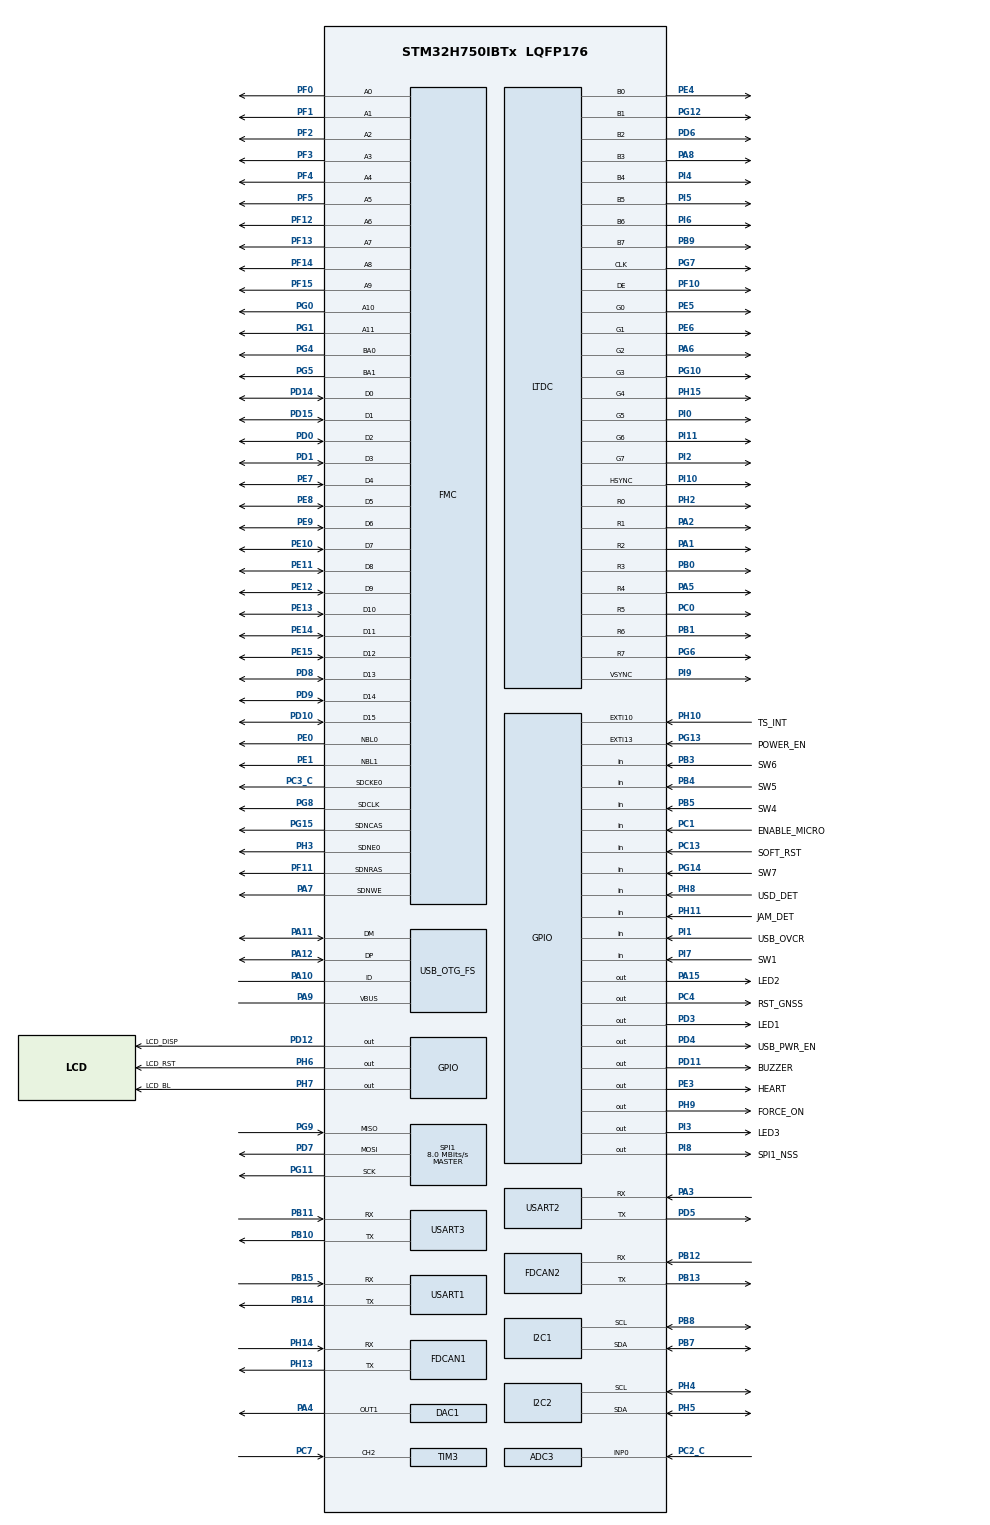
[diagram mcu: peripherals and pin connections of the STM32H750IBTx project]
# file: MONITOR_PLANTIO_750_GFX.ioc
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ADC3.Channel-0\#ChannelRegularConversion=ADC_CHANNEL_0
ADC3.ContinuousConvMode=ENABLE
ADC3.ConversionDataManagement=ADC_CONVERSIONDATA_DMA_CIRCULAR
ADC3.NbrOfConversionFlag=1
ADC3.OffsetNumber-0\#ChannelRegularConversion=ADC_OFFSET_NONE
ADC3.OffsetSignedSaturation-0\#ChannelRegularConversion=DISABLE
ADC3.Rank-0\#ChannelRegularConversion=1
ADC3.Resolution=ADC_RESOLUTION_12B
ADC3.SamplingTime-0\#ChannelRegularConversion=ADC_SAMPLETIME_1CYCLE_5
Bdma.ADC3.0.Direction=DMA_PERIPH_TO_MEMORY
Bdma.ADC3.0.EventEnable=DISABLE
Bdma.ADC3.0.Instance=BDMA_Channel0
Bdma.ADC3.0.MemDataAlignment=DMA_MDATAALIGN_HALFWORD
Bdma.ADC3.0.MemInc=DMA_MINC_ENABLE
Bdma.ADC3.0.Mode=DMA_CIRCULAR
Bdma.ADC3.0.PeriphDataAlignment=DMA_PDATAALIGN_HALFWORD
Bdma.ADC3.0.PeriphInc=DMA_PINC_DISABLE
Bdma.ADC3.0.Polarity=HAL_DMAMUX_REQ_GEN_RISING
Bdma.ADC3.0.Priority=DMA_PRIORITY_LOW
Bdma.ADC3.0.RequestNumber=1
Bdma.ADC3.0.SignalID=NONE
Bdma.ADC3.0.SyncEnable=DISABLE
Bdma.ADC3.0.SyncPolarity=HAL_DMAMUX_SYNC_NO_EVENT
Bdma.ADC3.0.SyncRequestNumber=1
Bdma.ADC3.0.SyncSignalID=NONE
Bdma.Request0=ADC3
Bdma.RequestsNb=1
CORTEX_M7.AccessPermission_S-Cortex_Memory_Protection_Unit_Region1_Settings_S=MPU_REGION_FULL_ACCESS
CORTEX_M7.AccessPermission_Spec=MPU_REGION_FULL_ACCESS
CORTEX_M7.BaseAddress_S-Cortex_Memory_Protection_Unit_Region1_Settings_S=0x90000000
CORTEX_M7.BaseAddress_Spec=0x90000000
CORTEX_M7.CPU_DCache=Enabled
CORTEX_M7.CPU_ICache=Enabled
CORTEX_M7.Enable_S-Cortex_Memory_Protection_Unit_Region1_Settings_S=MPU_REGION_ENABLE
CORTEX_M7.IsBufferable_S-Cortex_Memory_Protection_Unit_Region1_Settings_S=MPU_ACCESS_BUFFERABLE
CORTEX_M7.IsBufferable_Spec=MPU_ACCESS_BUFFERABLE
CORTEX_M7.IsCacheable_S-Cortex_Memory_Protection_Unit_Region1_Settings_S=MPU_ACCESS_CACHEABLE
CORTEX_M7.IsCacheable_Spec=MPU_ACCESS_CACHEABLE
CORTEX_M7.IsShareable_Spec=MPU_ACCESS_NOT_SHAREABLE
CORTEX_M7.Size_S-Cortex_Memory_Protection_Unit_Region1_Settings_S=MPU_REGION_SIZE_16MB
CORTEX_M7.Size_Spec=MPU_REGION_SIZE_64MB
CORTEX_M7.SubRegionDisable_Spec=0
CORTEX_M7.default_mode_Activation=1
DAC1.DAC_Channel-DAC_OUT1=DAC_CHANNEL_1
DMA2D.AlphaInvertedForeground=DMA2D_REGULAR_ALPHA
DMA2D.AlphaModeForeground=DMA2D_NO_MODIF_ALPHA
DMA2D.ColorMode=DMA2D_OUTPUT_RGB565
DMA2D.InputAlphaForeground=255
FDCAN1.AutoRetransmission=ENABLE
FDCAN1.CalculateBaudRateNominal=250000
FDCAN1.CalculateTimeBitNominal=4000
FDCAN1.CalculateTimeQuantumNominal=40.0
FDCAN1.DataPrescaler=4
FDCAN1.DataSyncJumpWidth=12
FDCAN1.DataTimeSeg1=12
FDCAN1.DataTimeSeg2=12
FDCAN1.ExtFiltersNbr=1
FDCAN1.NominalPrescaler=1
FDCAN1.NominalSyncJumpWidth=2
FDCAN1.NominalTimeSeg1=97
FDCAN1.NominalTimeSeg2=2
FDCAN1.RxFifo0ElmtsNbr=1
FDCAN1.TxBuffersNbr=16
FDCAN1.TxEventsNbr=1
FDCAN1.TxFifoQueueElmtsNbr=16
FDCAN2.AutoRetransmission=ENABLE
FDCAN2.CalculateBaudRateNominal=250000
FDCAN2.CalculateTimeBitNominal=4000
FDCAN2.CalculateTimeQuantumNominal=40.0
FDCAN2.DataPrescaler=4
FDCAN2.DataSyncJumpWidth=12
FDCAN2.DataTimeSeg1=12
FDCAN2.DataTimeSeg2=12
FDCAN2.ExtFiltersNbr=1
FDCAN2.MessageRAMOffset=10
FDCAN2.NominalPrescaler=1
FDCAN2.NominalSyncJumpWidth=2
FDCAN2.NominalTimeSeg1=97
FDCAN2.NominalTimeSeg2=2
FDCAN2.RxFifo1ElmtsNbr=1
FDCAN2.TxBuffersNbr=16
FDCAN2.TxEventsNbr=1
FDCAN2.TxFifoQueueElmtsNbr=16
FMC.CASLatency1=FMC_SDRAM_CAS_LATENCY_3
FMC.ExitSelfRefreshDelay1=11
FMC.LoadToActiveDelay1=2
FMC.RCDDelay1=3
FMC.RPDelay1=3
FMC.RPDelay2=3
FMC.ReadBurst1=FMC_SDRAM_RBURST_ENABLE
FMC.ReadBurst2=FMC_SDRAM_RBURST_ENABLE
FMC.ReadPipeDelay1=FMC_SDRAM_RPIPE_DELAY_2
FMC.RowCycleDelay1=10
FMC.RowCycleDelay2=10
FMC.SDClockPeriod1=FMC_SDRAM_CLOCK_PERIOD_3
FMC.SDClockPeriod2=FMC_SDRAM_CLOCK_PERIOD_3
FMC.SelfRefreshTime1=7
FMC.WriteRecoveryTime1=4
FREERTOS.Queues01=adcQueue,4,uint16_t,0,Dynamic,NULL,NULL;butQueue,8,uint8_t,0,Dynamic,NULL,NULL;ts_Touch,12,uint16_t,0,Dynamic,NULL,NULL;canQueue,64,uint8_t,0,Dynamic,NULL,NULL
FREERTOS.Tasks01=defaultTask,24,128,StartDefaultTask,Default,NULL,Dynamic,NULL,NULL;myTouchGFX,24,10000,StartTGFXTask,Default,NULL,Dynamic,NULL,NULL;adcTask,16,512,StartADCTask,Default,NULL,Dynamic,NULL,NULL;tsTask,25,1000,StartTS,Default,NULL,Dynamic,NULL,NULL;CanTask,24,512,StartTask05,Default,NULL,Dynamic,NULL,NULL
FREERTOS.configTOTAL_HEAP_SIZE=50000
FREERTOS.configUSE_NEWLIB_REENTRANT=1
I2C1.Timing=0x307075B1
I2C2.Timing=0x307075B1
LTDC.ActiveW=800
LTDC.Alpha0_L0=255
LTDC.Alpha_L0=255
LTDC.BlendingFactor1_L0=LTDC_BLENDING_FACTOR1_PAxCA
LTDC.BlendingFactor2_L0=LTDC_BLENDING_FACTOR2_PAxCA
LTDC.Blue_L0=0
LTDC.DEPolarity=LTDC_DEPOLARITY_AL
LTDC.FBStartAdress_L0=0xC0000000
LTDC.Green_L0=0
LTDC.HBP=24
LTDC.HFP=16
LTDC.HSPolarity=LTDC_HSPOLARITY_AL
LTDC.HSync=9
LTDC.ImageHeight_L0=480
LTDC.ImageWidth_L0=800
LTDC.Layers=0
LTDC.PCPolarity=LTDC_PCPOLARITY_IPC
LTDC.PixelFormat_L0=LTDC_PIXEL_FORMAT_RGB565
LTDC.Red_L0=0
LTDC.VBP=16
LTDC.VFP=8
LTDC.VSPolarity=LTDC_VSPOLARITY_AL
LTDC.VSync=9
LTDC.WindowX1_L0=800
LTDC.WindowY1_L0=480
Mcu.Family=STM32H7
Mcu.Name=STM32H750IBTx
Mcu.Package=LQFP176
NVIC.BDMA_Channel0_IRQn=true\:5\:0\:false\:false\:true\:true\:false\:true\:true
NVIC.DMA2D_IRQn=true\:5\:0\:false\:false\:true\:true\:true\:true\:true
NVIC.FDCAN1_IT0_IRQn=true\:5\:0\:true\:false\:true\:true\:true\:true\:true
NVIC.FDCAN2_IT1_IRQn=true\:5\:0\:true\:false\:true\:true\:true\:true\:true
NVIC.LTDC_IRQn=true\:5\:0\:true\:false\:true\:true\:true\:true\:true
NVIC.PriorityGroup=NVIC_PRIORITYGROUP_4
NVIC.TIM6_DAC_IRQn=true\:15\:0\:false\:false\:true\:false\:false\:true\:true
NVIC.TIM7_IRQn=true\:8\:0\:true\:false\:true\:true\:true\:true\:true
NVIC.TimeBase=TIM6_DAC_IRQn
NVIC.TimeBaseIP=TIM6
PA1.GPIO_Speed=GPIO_SPEED_FREQ_VERY_HIGH
PA1.Mode=RGB888
PA1.PinAttribute=Free
PA1.Signal=LTDC_R2
PA10.Mode=OTG/Dual_Role_Device
PA10.PinAttribute=Free
PA10.Signal=USB_OTG_FS_ID
PA11.Mode=OTG/Dual_Role_Device
PA11.PinAttribute=Free
PA11.Signal=USB_OTG_FS_DM
PA12.Mode=OTG/Dual_Role_Device
PA12.PinAttribute=Free
PA12.Signal=USB_OTG_FS_DP
PA13\ (JTMS/SWDIO).Mode=Serial_Wire
PA13\ (JTMS/SWDIO).PinAttribute=Free
PA13\ (JTMS/SWDIO).Signal=DEBUG_JTMS-SWDIO
PA14\ (JTCK/SWCLK).Mode=Serial_Wire
PA14\ (JTCK/SWCLK).PinAttribute=Free
PA14\ (JTCK/SWCLK).Signal=DEBUG_JTCK-SWCLK
PA15\ (JTDI).GPIO_Label=LED2
PA15\ (JTDI).PinAttribute=Free
PA15\ (JTDI).Signal=GPIO_Output
PA2.GPIO_Speed=GPIO_SPEED_FREQ_VERY_HIGH
PA2.Mode=RGB888
PA2.PinAttribute=Free
PA2.Signal=LTDC_R1
PA3.Mode=Asynchronous
PA3.PinAttribute=Free
PA3.Signal=USART2_RX
PA4.PinAttribute=Free
PA4.Signal=COMP_DAC11_group
PA5.GPIO_Speed=GPIO_SPEED_FREQ_VERY_HIGH
PA5.Mode=RGB888
PA5.PinAttribute=Free
PA5.Signal=LTDC_R4
PA6.GPIO_Speed=GPIO_SPEED_FREQ_VERY_HIGH
PA6.Mode=RGB888
PA6.PinAttribute=Free
PA6.Signal=LTDC_G2
PA7.GPIO_PuPd=GPIO_NOPULL
PA7.GPIO_Speed_High_Default=GPIO_SPEED_FREQ_VERY_HIGH
PA7.PinAttribute=Free
PA7.Signal=FMC_SDNWE
PA8.GPIO_Speed=GPIO_SPEED_FREQ_VERY_HIGH
PA8.Mode=RGB888
PA8.PinAttribute=Free
PA8.Signal=LTDC_B3
PA9.Mode=Activate_VBUS
PA9.PinAttribute=Free
PA9.Signal=USB_OTG_FS_VBUS
PB0.GPIO_Speed=GPIO_SPEED_FREQ_VERY_HIGH
PB0.Mode=RGB888
PB0.PinAttribute=Free
PB0.Signal=LTDC_R3
PB1.GPIO_Speed=GPIO_SPEED_FREQ_VERY_HIGH
PB1.Mode=RGB888
PB1.PinAttribute=Free
PB1.Signal=LTDC_R6
PB10.Mode=Asynchronous
PB10.PinAttribute=Free
PB10.Signal=USART3_TX
PB11.Mode=Asynchronous
PB11.PinAttribute=Free
PB11.Signal=USART3_RX
PB12.Mode=FDCAN_Activate
PB12.PinAttribute=Free
PB12.Signal=FDCAN2_RX
PB13.Mode=FDCAN_Activate
PB13.PinAttribute=Free
PB13.Signal=FDCAN2_TX
PB14.Mode=Asynchronous
PB14.PinAttribute=Free
PB14.Signal=USART1_TX
PB15.Mode=Asynchronous
PB15.PinAttribute=Free
PB15.Signal=USART1_RX
PB3\ (JTDO/TRACESWO).GPIO_Label=SW6
PB3\ (JTDO/TRACESWO).PinAttribute=Free
PB3\ (JTDO/TRACESWO).Signal=GPIO_Input
PB4\ (NJTRST).GPIO_Label=SW5
PB4\ (NJTRST).PinAttribute=Free
PB4\ (NJTRST).Signal=GPIO_Input
PB5.GPIO_Label=SW4
PB5.PinAttribute=Free
PB5.Signal=GPIO_Input
PB7.GPIO_Speed=GPIO_SPEED_FREQ_HIGH
PB7.Mode=I2C
PB7.PinAttribute=Free
PB7.Signal=I2C1_SDA
PB8.GPIO_Speed=GPIO_SPEED_FREQ_HIGH
PB8.Mode=I2C
PB8.PinAttribute=Free
PB8.Signal=I2C1_SCL
PB9.GPIO_Speed=GPIO_SPEED_FREQ_VERY_HIGH
PB9.Mode=RGB888
PB9.PinAttribute=Free
PB9.Signal=LTDC_B7
PC0.GPIO_Speed=GPIO_SPEED_FREQ_VERY_HIGH
PC0.Mode=RGB888
PC0.PinAttribute=Free
PC0.Signal=LTDC_R5
PC1.GPIO_Label=ENABLE_MICRO
PC1.PinAttribute=Free
PC1.Signal=GPIO_Input
PC13.GPIO_Label=SOFT_RST
PC13.PinAttribute=Free
PC13.Signal=GPIO_Input
PC2_C.Mode=IN0-Single-Ended
PC2_C.PinAttribute=Free
PC2_C.Signal=ADC3_INP0
PC3_C.GPIO_PuPd=GPIO_NOPULL
PC3_C.GPIO_Speed_High_Default=GPIO_SPEED_FREQ_VERY_HIGH
PC3_C.Mode=SdramChipSelect1_1
PC3_C.PinAttribute=Free
PC3_C.Signal=FMC_SDCKE0
PC4.GPIO_Label=RST_GNSS
PC4.PinAttribute=Free
PC4.Signal=GPIO_Output
PC7.PinAttribute=Free
PC7.Signal=S_TIM3_CH2
PD0.GPIO_PuPd=GPIO_NOPULL
PD0.GPIO_Speed_High_Default=GPIO_SPEED_FREQ_VERY_HIGH
PD0.PinAttribute=Free
PD0.Signal=FMC_D2_DA2
PD1.GPIO_PuPd=GPIO_NOPULL
PD1.GPIO_Speed_High_Default=GPIO_SPEED_FREQ_VERY_HIGH
PD1.PinAttribute=Free
PD1.Signal=FMC_D3_DA3
PD10.GPIO_PuPd=GPIO_NOPULL
PD10.GPIO_Speed_High_Default=GPIO_SPEED_FREQ_VERY_HIGH
PD10.PinAttribute=Free
PD10.Signal=FMC_D15_DA15
PD11.GPIO_Label=BUZZER
PD11.PinAttribute=Free
PD11.Signal=GPIO_Output
PD12.GPIO_Label=LCD_DISP
PD12.PinAttribute=Free
PD12.Signal=GPIO_Output
PD14.GPIO_PuPd=GPIO_NOPULL
PD14.GPIO_Speed_High_Default=GPIO_SPEED_FREQ_VERY_HIGH
PD14.PinAttribute=Free
PD14.Signal=FMC_D0_DA0
PD15.GPIO_PuPd=GPIO_NOPULL
PD15.GPIO_Speed_High_Default=GPIO_SPEED_FREQ_VERY_HIGH
PD15.PinAttribute=Free
PD15.Signal=FMC_D1_DA1
PD3.GPIO_Label=LED1
PD3.PinAttribute=Free
PD3.Signal=GPIO_Output
PD4.GPIO_Label=USB_PWR_EN
PD4.PinAttribute=Free
PD4.Signal=GPIO_Output
PD5.Mode=Asynchronous
PD5.PinAttribute=Free
PD5.Signal=USART2_TX
PD6.GPIO_Speed=GPIO_SPEED_FREQ_VERY_HIGH
PD6.Mode=RGB888
PD6.PinAttribute=Free
PD6.Signal=LTDC_B2
PD7.Mode=Full_Duplex_Master
PD7.PinAttribute=Free
PD7.Signal=SPI1_MOSI
PD8.GPIO_PuPd=GPIO_NOPULL
PD8.GPIO_Speed_High_Default=GPIO_SPEED_FREQ_VERY_HIGH
PD8.PinAttribute=Free
PD8.Signal=FMC_D13_DA13
PD9.GPIO_PuPd=GPIO_NOPULL
PD9.GPIO_Speed_High_Default=GPIO_SPEED_FREQ_VERY_HIGH
PD9.PinAttribute=Free
PD9.Signal=FMC_D14_DA14
PE0.PinAttribute=Free
PE0.Signal=FMC_NBL0
PE1.PinAttribute=Free
PE1.Signal=FMC_NBL1
PE10.GPIO_PuPd=GPIO_NOPULL
PE10.GPIO_Speed_High_Default=GPIO_SPEED_FREQ_VERY_HIGH
PE10.PinAttribute=Free
PE10.Signal=FMC_D7_DA7
PE11.GPIO_PuPd=GPIO_NOPULL
PE11.GPIO_Speed_High_Default=GPIO_SPEED_FREQ_VERY_HIGH
PE11.PinAttribute=Free
PE11.Signal=FMC_D8_DA8
PE12.GPIO_PuPd=GPIO_NOPULL
PE12.GPIO_Speed_High_Default=GPIO_SPEED_FREQ_VERY_HIGH
PE12.PinAttribute=Free
PE12.Signal=FMC_D9_DA9
PE13.GPIO_PuPd=GPIO_NOPULL
PE13.GPIO_Speed_High_Default=GPIO_SPEED_FREQ_VERY_HIGH
PE13.PinAttribute=Free
PE13.Signal=FMC_D10_DA10
PE14.GPIO_PuPd=GPIO_NOPULL
PE14.GPIO_Speed_High_Default=GPIO_SPEED_FREQ_VERY_HIGH
PE14.PinAttribute=Free
PE14.Signal=FMC_D11_DA11
PE15.GPIO_PuPd=GPIO_NOPULL
PE15.GPIO_Speed_High_Default=GPIO_SPEED_FREQ_VERY_HIGH
PE15.PinAttribute=Free
PE15.Signal=FMC_D12_DA12
PE3.GPIO_Label=HEART
PE3.PinAttribute=Free
PE3.Signal=GPIO_Output
PE4.GPIO_Speed=GPIO_SPEED_FREQ_VERY_HIGH
PE4.Mode=RGB888
PE4.PinAttribute=Free
PE4.Signal=LTDC_B0
PE5.GPIO_Speed=GPIO_SPEED_FREQ_VERY_HIGH
PE5.Mode=RGB888
PE5.PinAttribute=Free
PE5.Signal=LTDC_G0
PE6.GPIO_Speed=GPIO_SPEED_FREQ_VERY_HIGH
PE6.Mode=RGB888
PE6.PinAttribute=Free
PE6.Signal=LTDC_G1
PE7.GPIO_PuPd=GPIO_NOPULL
PE7.GPIO_Speed_High_Default=GPIO_SPEED_FREQ_VERY_HIGH
PE7.PinAttribute=Free
PE7.Signal=FMC_D4_DA4
PE8.GPIO_PuPd=GPIO_NOPULL
PE8.GPIO_Speed_High_Default=GPIO_SPEED_FREQ_VERY_HIGH
PE8.PinAttribute=Free
PE8.Signal=FMC_D5_DA5
PE9.GPIO_PuPd=GPIO_NOPULL
PE9.GPIO_Speed_High_Default=GPIO_SPEED_FREQ_VERY_HIGH
PE9.PinAttribute=Free
PE9.Signal=FMC_D6_DA6
PF0.GPIO_PuPd=GPIO_NOPULL
PF0.GPIO_Speed_High_Default=GPIO_SPEED_FREQ_VERY_HIGH
PF0.PinAttribute=Free
PF0.Signal=FMC_A0
PF1.GPIO_PuPd=GPIO_NOPULL
PF1.GPIO_Speed_High_Default=GPIO_SPEED_FREQ_VERY_HIGH
PF1.PinAttribute=Free
PF1.Signal=FMC_A1
PF10.GPIO_Speed=GPIO_SPEED_FREQ_VERY_HIGH
PF10.Mode=RGB888
PF10.PinAttribute=Free
PF10.Signal=LTDC_DE
PF11.GPIO_PuPd=GPIO_NOPULL
PF11.GPIO_Speed_High_Default=GPIO_SPEED_FREQ_VERY_HIGH
PF11.PinAttribute=Free
PF11.Signal=FMC_SDNRAS
PF12.GPIO_PuPd=GPIO_NOPULL
PF12.GPIO_Speed_High_Default=GPIO_SPEED_FREQ_VERY_HIGH
PF12.PinAttribute=Free
PF12.Signal=FMC_A6
PF13.GPIO_PuPd=GPIO_NOPULL
PF13.GPIO_Speed_High_Default=GPIO_SPEED_FREQ_VERY_HIGH
PF13.PinAttribute=Free
PF13.Signal=FMC_A7
PF14.GPIO_PuPd=GPIO_NOPULL
PF14.GPIO_Speed_High_Default=GPIO_SPEED_FREQ_VERY_HIGH
PF14.PinAttribute=Free
PF14.Signal=FMC_A8
PF15.GPIO_PuPd=GPIO_NOPULL
PF15.GPIO_Speed_High_Default=GPIO_SPEED_FREQ_VERY_HIGH
PF15.PinAttribute=Free
PF15.Signal=FMC_A9
PF2.GPIO_PuPd=GPIO_NOPULL
PF2.GPIO_Speed_High_Default=GPIO_SPEED_FREQ_VERY_HIGH
PF2.PinAttribute=Free
PF2.Signal=FMC_A2
PF3.GPIO_PuPd=GPIO_NOPULL
PF3.GPIO_Speed_High_Default=GPIO_SPEED_FREQ_VERY_HIGH
PF3.PinAttribute=Free
PF3.Signal=FMC_A3
PF4.GPIO_PuPd=GPIO_NOPULL
PF4.GPIO_Speed_High_Default=GPIO_SPEED_FREQ_VERY_HIGH
PF4.PinAttribute=Free
PF4.Signal=FMC_A4
PF5.GPIO_PuPd=GPIO_NOPULL
PF5.GPIO_Speed_High_Default=GPIO_SPEED_FREQ_VERY_HIGH
PF5.PinAttribute=Free
PF5.Signal=FMC_A5
PG0.GPIO_PuPd=GPIO_NOPULL
PG0.GPIO_Speed_High_Default=GPIO_SPEED_FREQ_VERY_HIGH
PG0.PinAttribute=Free
PG0.Signal=FMC_A10
PG1.GPIO_PuPd=GPIO_NOPULL
PG1.GPIO_Speed_High_Default=GPIO_SPEED_FREQ_VERY_HIGH
PG1.PinAttribute=Free
PG1.Signal=FMC_A11
PG10.GPIO_Speed=GPIO_SPEED_FREQ_VERY_HIGH
PG10.Mode=RGB888
PG10.PinAttribute=Free
PG10.Signal=LTDC_G3
PG11.Mode=Full_Duplex_Master
PG11.Signal=SPI1_SCK
PG12.GPIO_Speed=GPIO_SPEED_FREQ_VERY_HIGH
PG12.Mode=RGB888
PG12.PinAttribute=Free
PG12.Signal=LTDC_B1
PG13.GPIO_Label=POWER_EN
PG13.PinAttribute=Free
PG13.Signal=GPXTI13
PG14.GPIO_Label=SW7
PG14.PinAttribute=Free
PG14.Signal=GPIO_Input
PG15.GPIO_PuPd=GPIO_NOPULL
PG15.GPIO_Speed_High_Default=GPIO_SPEED_FREQ_VERY_HIGH
PG15.PinAttribute=Free
PG15.Signal=FMC_SDNCAS
PG4.GPIO_PuPd=GPIO_NOPULL
PG4.GPIO_Speed_High_Default=GPIO_SPEED_FREQ_VERY_HIGH
PG4.PinAttribute=Free
PG4.Signal=FMC_A14_BA0
PG5.GPIO_PuPd=GPIO_NOPULL
PG5.GPIO_Speed_High_Default=GPIO_SPEED_FREQ_VERY_HIGH
PG5.PinAttribute=Free
PG5.Signal=FMC_A15_BA1
PG6.GPIO_Speed=GPIO_SPEED_FREQ_VERY_HIGH
PG6.Mode=RGB888
PG6.PinAttribute=Free
PG6.Signal=LTDC_R7
PG7.GPIO_Speed=GPIO_SPEED_FREQ_VERY_HIGH
PG7.Mode=RGB888
PG7.PinAttribute=Free
PG7.Signal=LTDC_CLK
PG8.GPIO_PuPd=GPIO_NOPULL
PG8.GPIO_Speed_High_Default=GPIO_SPEED_FREQ_VERY_HIGH
PG8.PinAttribute=Free
PG8.Signal=FMC_SDCLK
PG9.Mode=Full_Duplex_Master
PG9.PinAttribute=Free
PG9.Signal=SPI1_MISO
PH0-OSC_IN\ (PH0).Mode=HSE-External-Oscillator
PH0-OSC_IN\ (PH0).PinAttribute=Free
PH0-OSC_IN\ (PH0).Signal=RCC_OSC_IN
PH1-OSC_OUT\ (PH1).Mode=HSE-External-Oscillator
PH1-OSC_OUT\ (PH1).PinAttribute=Free
PH1-OSC_OUT\ (PH1).Signal=RCC_OSC_OUT
PH10.GPIO_Label=TS_INT
PH10.PinAttribute=Free
PH10.Signal=GPXTI10
PH11.GPIO_Label=JAM_DET
PH11.PinAttribute=Free
PH11.Signal=GPIO_Input
PH13.Mode=FDCAN_Activate
PH13.PinAttribute=Free
PH13.Signal=FDCAN1_TX
PH14.Mode=FDCAN_Activate
PH14.PinAttribute=Free
PH14.Signal=FDCAN1_RX
PH15.GPIO_Speed=GPIO_SPEED_FREQ_VERY_HIGH
PH15.Mode=RGB888
PH15.PinAttribute=Free
PH15.Signal=LTDC_G4
PH2.GPIO_Speed=GPIO_SPEED_FREQ_VERY_HIGH
PH2.Mode=RGB888
PH2.PinAttribute=Free
PH2.Signal=LTDC_R0
PH3.GPIO_PuPd=GPIO_NOPULL
PH3.GPIO_Speed_High_Default=GPIO_SPEED_FREQ_VERY_HIGH
PH3.Mode=SdramChipSelect1_1
PH3.PinAttribute=Free
PH3.Signal=FMC_SDNE0
PH4.Mode=I2C
PH4.PinAttribute=Free
PH4.Signal=I2C2_SCL
PH5.Mode=I2C
PH5.PinAttribute=Free
PH5.Signal=I2C2_SDA
PH6.GPIO_Label=LCD_RST
PH6.PinAttribute=Free
PH6.Signal=GPIO_Output
PH7.GPIO_Label=LCD_BL
PH7.PinAttribute=Free
PH7.Signal=GPIO_Output
PH8.GPIO_Label=USD_DET
PH8.PinAttribute=Free
PH8.Signal=GPIO_Input
PH9.GPIO_Label=FORCE_ON
PH9.PinAttribute=Free
PH9.Signal=GPIO_Output
PI0.GPIO_Speed=GPIO_SPEED_FREQ_VERY_HIGH
PI0.Mode=RGB888
PI0.PinAttribute=Free
PI0.Signal=LTDC_G5
PI1.GPIO_Label=USB_OVCR
PI1.PinAttribute=Free
PI1.Signal=GPIO_Input
PI10.GPIO_Speed=GPIO_SPEED_FREQ_VERY_HIGH
PI10.Mode=RGB888
PI10.PinAttribute=Free
PI10.Signal=LTDC_HSYNC
PI11.GPIO_Speed=GPIO_SPEED_FREQ_VERY_HIGH
PI11.Mode=RGB888
PI11.PinAttribute=Free
PI11.Signal=LTDC_G6
PI2.GPIO_Speed=GPIO_SPEED_FREQ_VERY_HIGH
PI2.Mode=RGB888
PI2.PinAttribute=Free
PI2.Signal=LTDC_G7
PI3.GPIO_Label=LED3
PI3.PinAttribute=Free
PI3.Signal=GPIO_Output
PI4.GPIO_Speed=GPIO_SPEED_FREQ_VERY_HIGH
PI4.Mode=RGB888
PI4.PinAttribute=Free
PI4.Signal=LTDC_B4
PI5.GPIO_Speed=GPIO_SPEED_FREQ_VERY_HIGH
PI5.Mode=RGB888
PI5.PinAttribute=Free
PI5.Signal=LTDC_B5
PI6.GPIO_Speed=GPIO_SPEED_FREQ_VERY_HIGH
PI6.Mode=RGB888
PI6.PinAttribute=Free
PI6.Signal=LTDC_B6
PI7.GPIO_Label=SW1
PI7.PinAttribute=Free
PI7.Signal=GPIO_Input
PI8.GPIO_Label=SPI1_NSS
PI8.PinAttribute=Free
PI8.Signal=GPIO_Output
PI9.GPIO_Speed=GPIO_SPEED_FREQ_VERY_HIGH
PI9.Mode=RGB888
PI9.PinAttribute=Free
PI9.Signal=LTDC_VSYNC
ProjectManager.HeapSize=0x1000
ProjectManager.StackSize=0x2000
ProjectManager.TargetToolchain=STM32CubeIDE
RCC.ADCFreq_Value=75000000
RCC.APB1Freq_Value=120000000
RCC.APB2Freq_Value=120000000
RCC.APB3Freq_Value=120000000
RCC.APB4Freq_Value=120000000
RCC.CortexFreq_Value=480000000
RCC.D1PPRE=RCC_APB3_DIV2
RCC.D2PPRE1=RCC_APB1_DIV2
RCC.D2PPRE2=RCC_APB2_DIV2
RCC.D3PPRE=RCC_APB4_DIV2
RCC.DIVM1=5
RCC.DIVM2=2
RCC.DIVM3=2
RCC.DIVN1=192
RCC.DIVN2=12
RCC.DIVN3=12
RCC.DIVQ1=15
RCC.DIVR2=1
RCC.DIVR3=6
RCC.FDCANCLockSelection=RCC_FDCANCLKSOURCE_HSE
RCC.HCLKFreq_Value=240000000
RCC.HPRE=RCC_HCLK_DIV2
RCC.LSE_VALUE=0.03277
RCC.PLL1_VCI_Range-AdvancedSettings=RCC_PLL1VCIRANGE_2
RCC.PLL1_VCO_SEL-AdvancedSettings=RCC_PLL1VCOMEDIUM
RCC.PLL2FRACN=0
RCC.PLL2_VCI_Range-AdvancedSettings=RCC_PLL2VCIRANGE_0
RCC.PLL3FRACN=0
RCC.PLLFRACN=0
RCC.PWR_Regulator_Voltage_Scale=PWR_REGULATOR_VOLTAGE_SCALE0
RCC.QSPICLockSelection=RCC_QSPICLKSOURCE_PLL2
RCC.SYSCLKFreq_VALUE=480000000
RCC.SYSCLKSource=RCC_SYSCLKSOURCE_PLLCLK
RCC.USBFreq_Value=64000000
SH.COMP_DAC11_group.0=DAC1_OUT1,DAC_OUT1
SH.FMC_A0.0=FMC_A0,12b-sda1
SH.FMC_A1.0=FMC_A1,12b-sda1
SH.FMC_A10.0=FMC_A10,12b-sda1
SH.FMC_A11.0=FMC_A11,12b-sda1
SH.FMC_A14_BA0.0=FMC_BA0,FourSdramBanks1
SH.FMC_A15_BA1.0=FMC_BA1,FourSdramBanks1
SH.FMC_A2.0=FMC_A2,12b-sda1
SH.FMC_A3.0=FMC_A3,12b-sda1
SH.FMC_A4.0=FMC_A4,12b-sda1
SH.FMC_A5.0=FMC_A5,12b-sda1
SH.FMC_A6.0=FMC_A6,12b-sda1
SH.FMC_A7.0=FMC_A7,12b-sda1
SH.FMC_A8.0=FMC_A8,12b-sda1
SH.FMC_A9.0=FMC_A9,12b-sda1
SH.FMC_D0_DA0.0=FMC_D0,sd-16b-d1
SH.FMC_D10_DA10.0=FMC_D10,sd-16b-d1
SH.FMC_D11_DA11.0=FMC_D11,sd-16b-d1
SH.FMC_D12_DA12.0=FMC_D12,sd-16b-d1
SH.FMC_D13_DA13.0=FMC_D13,sd-16b-d1
SH.FMC_D14_DA14.0=FMC_D14,sd-16b-d1
SH.FMC_D15_DA15.0=FMC_D15,sd-16b-d1
SH.FMC_D1_DA1.0=FMC_D1,sd-16b-d1
SH.FMC_D2_DA2.0=FMC_D2,sd-16b-d1
SH.FMC_D3_DA3.0=FMC_D3,sd-16b-d1
SH.FMC_D4_DA4.0=FMC_D4,sd-16b-d1
SH.FMC_D5_DA5.0=FMC_D5,sd-16b-d1
SH.FMC_D6_DA6.0=FMC_D6,sd-16b-d1
SH.FMC_D7_DA7.0=FMC_D7,sd-16b-d1
SH.FMC_D8_DA8.0=FMC_D8,sd-16b-d1
SH.FMC_D9_DA9.0=FMC_D9,sd-16b-d1
SH.FMC_NBL0.0=FMC_NBL0,Sd2ByteEnable1
SH.FMC_NBL1.0=FMC_NBL1,Sd2ByteEnable1
SH.FMC_SDCLK.0=FMC_SDCLK,12b-sda1
SH.FMC_SDNCAS.0=FMC_SDNCAS,12b-sda1
SH.FMC_SDNRAS.0=FMC_SDNRAS,12b-sda1
SH.FMC_SDNWE.0=FMC_SDNWE,12b-sda1
SH.S_TIM3_CH2.0=TIM3_CH2,Input_Capture2_from_TI2
SPI1.BaudRatePrescaler=SPI_BAUDRATEPRESCALER_8
SPI1.CalculateBaudRate=8.0 MBits/s
SPI1.Direction=SPI_DIRECTION_2LINES
SPI1.Mode=SPI_MODE_MASTER
SPI1.VirtualType=VM_MASTER
STMicroelectronics.X-CUBE-TOUCHGFX.4.26.1.ApplicationCcGraphicsJjApplication=TouchGFXOoGenerator
STMicroelectronics.X-CUBE-TOUCHGFX.4.26.1.tgfx_address1=0xC0000000
STMicroelectronics.X-CUBE-TOUCHGFX.4.26.1.tgfx_address2=0xC00BB800
STMicroelectronics.X-CUBE-TOUCHGFX.4.26.1.tgfx_buffering_strategy=Single
STMicroelectronics.X-CUBE-TOUCHGFX.4.26.1.tgfx_custom_height=480
STMicroelectronics.X-CUBE-TOUCHGFX.4.26.1.tgfx_display_interface=disp_ltdc
STMicroelectronics.X-CUBE-TOUCHGFX.4.26.1.tgfx_framebuffer_stride=Enabled
STMicroelectronics.X-CUBE-TOUCHGFX.4.26.1.tgfx_hardware_accelerator=dma_2d
STMicroelectronics.X-CUBE-TOUCHGFX.4.26.1.tgfx_location=By Address
STMicroelectronics.X-CUBE-TOUCHGFX.4.26.1.tgfx_oswrapper=CMSIS V2
STMicroelectronics.X-CUBE-TOUCHGFX.4.26.1.tgfx_pixel_format=RGB565\:16
STMicroelectronics.X-CUBE-TOUCHGFX.4.26.1.tgfx_vsync=vsync_ltdc
STMicroelectronics.X-CUBE-TOUCHGFX.4.26.1_IsPackSelfContextualization=true
TIM3.Channel-Input_Capture2_from_TI2=TIM_CHANNEL_2
TIM3.Prescaler=48-1
TIM7.Period=100-1
TIM7.Prescaler=480-1
USART1.VirtualMode-Asynchronous=VM_ASYNC
USART2.VirtualMode-Asynchronous=VM_ASYNC
USART3.VirtualMode-Asynchronous=VM_ASYNC
USB_OTG_FS.VirtualMode=Dual_Role_Device_FS
VP_CRC_VS_CRC.Mode=CRC_Activate
VP_DMA2D_VS_DMA2D.Mode=DMA2D_Activate
VP_FREERTOS_VS_CMSIS_V2.Mode=CMSIS_V2
VP_MEMORYMAP_VS_MEMORYMAP.Mode=CurAppReg
VP_STMicroelectronics.X-CUBE-TOUCHGFX_VS_GraphicsJjApplication_4.26.1.Mode=GraphicsJjApplication
VP_SYS_VS_tim6.Mode=TIM6
VP_TIM7_VS_ClockSourceINT.Mode=Enable_Timer
VP_USB_OTG_FS1_USB_OTG_FS_DRD.Mode=activate_FS
board=custom

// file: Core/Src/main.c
/* USER CODE BEGIN Header */
/**
  ******************************************************************************
  * @file           : main.c
  * @brief          : Main program body
  ******************************************************************************
  * @attention
  *
  * Copyright (c) 2026 STMicroelectronics.
  * All rights reserved.
  *
  * This software is licensed under terms that can be found in the LICENSE file
  * in the root directory of this software component.
  * If no LICENSE file comes with this software, it is provided AS-IS.
  *
  ******************************************************************************
  */
/* USER CODE END Header */
#include "main.h"
#include "FreeRTOS.h"
#include "cmsis_os2.h"
#include "adc.h"
#include "bdma.h"
#include "crc.h"
#include "dac.h"
#include "dma2d.h"
#include "fdcan.h"
#include "i2c.h"
#include "ltdc.h"
#include "spi.h"
#include "tim.h"
#include "usart.h"
#include "usb_otg.h"
#include "gpio.h"
#include "fmc.h"
#include "app_touchgfx.h"

/* USER CODE BEGIN Includes */
#include "touch.h"
/* USER CODE END Includes */

/* USER CODE BEGIN PD */
#define TFT_HOR_RES 800
#define TFT_VER_RES 480
#define TFT_BUFFER_SIZE (TFT_HOR_RES*TFT_VER_RES*2) //1152000 bytes

#define COLOR_BUF (((0x7f>>3)<<11)|((0x7f>>2)<<5)|(0x7f>>3)) // Convert colors to RGB565

/* USER CODE END PD */

/* USER CODE BEGIN PV */
uint16_t* framebuffer = (uint16_t*)0xC0000000;  //16 bpp framebuffer
/* USER CODE END PV */

void SystemClock_Config(void);
static void MPU_Config(void);
void MX_FREERTOS_Init(void);

/* USER CODE BEGIN 0 */
void delay_nop()
{
	__NOP();__NOP();__NOP();__NOP();__NOP();__NOP();__NOP();__NOP();__NOP();__NOP();__NOP();__NOP();
	__NOP();__NOP();__NOP();__NOP();__NOP();__NOP();
}

void delay_us(uint32_t delay)
 {
	uint32_t counter_delay=0;
	while(++counter_delay<delay)
	 {
		delay_nop();
	 }
 }
/* USER CODE END 0 */

int main(void)
{

  /* MPU Configuration--------------------------------------------------------*/
  MPU_Config();

  /* Enable the CPU Cache */

  /* Enable I-Cache---------------------------------------------------------*/
  SCB_EnableICache();

  /* Enable D-Cache---------------------------------------------------------*/
  SCB_EnableDCache();

  /* MCU Configuration--------------------------------------------------------*/

  /* Reset of all peripherals, Initializes the Flash interface and the Systick. */
  HAL_Init();

  /* USER CODE BEGIN Init */
   HAL_Delay(2000);
  /* USER CODE END Init */

  /* Configure the system clock */
  SystemClock_Config();

  /* USER CODE BEGIN SysInit */
  //
  //Step 1: Configure a clock configuration enable command

  /* USER CODE END SysInit */

  /* Initialize all configured peripherals */
  MX_GPIO_Init();
  MX_BDMA_Init();
  MX_ADC3_Init();
  MX_DAC1_Init();
  MX_FDCAN1_Init();
  MX_FDCAN2_Init();
  MX_FMC_Init();
  MX_I2C1_Init();
  MX_I2C2_Init();
  MX_LTDC_Init();
  MX_SPI1_Init();
  MX_USART1_UART_Init();
  MX_USART2_UART_Init();
  MX_USART3_UART_Init();
  MX_USB_OTG_FS_PCD_Init();
  MX_TIM7_Init();
  MX_CRC_Init();
  MX_DMA2D_Init();
  MX_TIM3_Init();
  MX_TouchGFX_Init();
  /* Call PreOsInit function */
  MX_TouchGFX_PreOSInit();
  /* USER CODE BEGIN 2 */
  HAL_GPIO_WritePin(LCD_BL_GPIO_Port, LCD_BL_Pin, 0);
  delay_us(50000); //5ms
  BSP_TS_Init(800,480);
  HAL_GPIO_WritePin(LCD_DISP_GPIO_Port,LCD_DISP_Pin, 0);
  delay_us(1000000); //100ms
  HAL_GPIO_WritePin(LCD_RST_GPIO_Port,LCD_RST_Pin, 0);
  delay_us(2500000); //250ms
  HAL_GPIO_WritePin(LCD_RST_GPIO_Port,LCD_RST_Pin, 1);
  delay_us(2500000); //250ms
  HAL_GPIO_WritePin(LCD_DISP_GPIO_Port,LCD_DISP_Pin, 1);
  delay_us(5000000); //500ms
  HAL_GPIO_WritePin(LCD_BL_GPIO_Port, LCD_BL_Pin, 1);
  HAL_I2C_Init(&hi2c1);
  /* USER CODE END 2 */

  /* Init scheduler */
  osKernelInitialize();  /* Call init function for freertos objects (in cmsis_os2.c) */
  MX_FREERTOS_Init();

  /* Start scheduler */
  osKernelStart();

  /* We should never get here as control is now taken by the scheduler */

  /* Infinite loop */
  while (1)
  {

  }
}

void SystemClock_Config(void)
{
  RCC_OscInitTypeDef RCC_OscInitStruct = {0};
  RCC_ClkInitTypeDef RCC_ClkInitStruct = {0};

  /** Supply configuration update enable
  */
  HAL_PWREx_ConfigSupply(PWR_LDO_SUPPLY);

  /** Configure the main internal regulator output voltage
  */
  __HAL_PWR_VOLTAGESCALING_CONFIG(PWR_REGULATOR_VOLTAGE_SCALE0);

  while(!__HAL_PWR_GET_FLAG(PWR_FLAG_VOSRDY)) {}

  /** Initializes the RCC Oscillators according to the specified parameters
  * in the RCC_OscInitTypeDef structure.
  */
  RCC_OscInitStruct.OscillatorType = RCC_OSCILLATORTYPE_HSE;
  RCC_OscInitStruct.HSEState = RCC_HSE_ON;
  RCC_OscInitStruct.PLL.PLLState = RCC_PLL_ON;
  RCC_OscInitStruct.PLL.PLLSource = RCC_PLLSOURCE_HSE;
  RCC_OscInitStruct.PLL.PLLM = 5;
  RCC_OscInitStruct.PLL.PLLN = 192;
  RCC_OscInitStruct.PLL.PLLP = 2;
  RCC_OscInitStruct.PLL.PLLQ = 15;
  RCC_OscInitStruct.PLL.PLLR = 2;
  RCC_OscInitStruct.PLL.PLLRGE = RCC_PLL1VCIRANGE_2;
  RCC_OscInitStruct.PLL.PLLVCOSEL = RCC_PLL1VCOWIDE;
  RCC_OscInitStruct.PLL.PLLFRACN = 0;
  if (HAL_RCC_OscConfig(&RCC_OscInitStruct) != HAL_OK)
  {
    Error_Handler();
  }

  /** Initializes the CPU, AHB and APB buses clocks
  */
  RCC_ClkInitStruct.ClockType = RCC_CLOCKTYPE_HCLK|RCC_CLOCKTYPE_SYSCLK
                              |RCC_CLOCKTYPE_PCLK1|RCC_CLOCKTYPE_PCLK2
                              |RCC_CLOCKTYPE_D3PCLK1|RCC_CLOCKTYPE_D1PCLK1;
  RCC_ClkInitStruct.SYSCLKSource = RCC_SYSCLKSOURCE_PLLCLK;
  RCC_ClkInitStruct.SYSCLKDivider = RCC_SYSCLK_DIV1;
  RCC_ClkInitStruct.AHBCLKDivider = RCC_HCLK_DIV2;
  RCC_ClkInitStruct.APB3CLKDivider = RCC_APB3_DIV2;
  RCC_ClkInitStruct.APB1CLKDivider = RCC_APB1_DIV2;
  RCC_ClkInitStruct.APB2CLKDivider = RCC_APB2_DIV2;
  RCC_ClkInitStruct.APB4CLKDivider = RCC_APB4_DIV2;

  if (HAL_RCC_ClockConfig(&RCC_ClkInitStruct, FLASH_LATENCY_4) != HAL_OK)
  {
    Error_Handler();
  }
}

 /* MPU Configuration */

void MPU_Config(void)
{
  MPU_Region_InitTypeDef MPU_InitStruct = {0};

  /* Disables the MPU */
  HAL_MPU_Disable();

  /** Initializes and configures the Region and the memory to be protected
  */
  MPU_InitStruct.Enable = MPU_REGION_ENABLE;
  MPU_InitStruct.Number = MPU_REGION_NUMBER0;
  MPU_InitStruct.BaseAddress = 0x90000000;
  MPU_InitStruct.Size = MPU_REGION_SIZE_64MB;
  MPU_InitStruct.SubRegionDisable = 0;
  MPU_InitStruct.TypeExtField = MPU_TEX_LEVEL0;
  MPU_InitStruct.AccessPermission = MPU_REGION_FULL_ACCESS;
  MPU_InitStruct.DisableExec = MPU_INSTRUCTION_ACCESS_DISABLE;
  MPU_InitStruct.IsShareable = MPU_ACCESS_NOT_SHAREABLE;
  MPU_InitStruct.IsCacheable = MPU_ACCESS_CACHEABLE;
  MPU_InitStruct.IsBufferable = MPU_ACCESS_BUFFERABLE;

  HAL_MPU_ConfigRegion(&MPU_InitStruct);

  /** Initializes and configures the Region and the memory to be protected
  */
  MPU_InitStruct.Number = MPU_REGION_NUMBER1;
  MPU_InitStruct.Size = MPU_REGION_SIZE_16MB;
  MPU_InitStruct.SubRegionDisable = 0x0;
  MPU_InitStruct.DisableExec = MPU_INSTRUCTION_ACCESS_ENABLE;

  HAL_MPU_ConfigRegion(&MPU_InitStruct);
  /* Enables the MPU */
  HAL_MPU_Enable(MPU_PRIVILEGED_DEFAULT);

}

void HAL_TIM_PeriodElapsedCallback(TIM_HandleTypeDef *htim)
{
  if (htim->Instance == TIM6)
  {
    HAL_IncTick();
  }
}

void Error_Handler(void)
{
  __disable_irq();
  while (1)
  {
  }
}

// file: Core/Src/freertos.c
/* USER CODE BEGIN Header */
/**
  ******************************************************************************
  * File Name          : freertos.c
  * Description        : Code for freertos applications
  ******************************************************************************
  * @attention
  *
  * Copyright (c) 2026 STMicroelectronics.
  * All rights reserved.
  *
  * This software is licensed under terms that can be found in the LICENSE file
  * in the root directory of this software component.
  * If no LICENSE file comes with this software, it is provided AS-IS.
  *
  ******************************************************************************
  */
/* USER CODE END Header */

#include "FreeRTOS.h"
#include "task.h"
#include "main.h"
#include "FreeRTOS.h"
#include "cmsis_os2.h"

/* USER CODE BEGIN Includes */
#include "app_touchgfx.h"
#include "keyboard.h"
#include "touch.h"
/* USER CODE END Includes */

/* USER CODE BEGIN PM */
extern ADC_HandleTypeDef hadc3;
extern DMA_HandleTypeDef hdma_adc3;
/* USER CODE END PM */

/* USER CODE BEGIN Variables */

uint16_t Voltage_in = 0;
/* USER CODE END Variables */
/* Definitions for defaultTask */
osThreadId_t defaultTaskHandle;
const osThreadAttr_t defaultTask_attributes = {
  .name = "defaultTask",
  .stack_size = 128 * 4,
  .priority = (osPriority_t) osPriorityNormal,
};
/* Definitions for myTouchGFX */
osThreadId_t myTouchGFXHandle;
const osThreadAttr_t myTouchGFX_attributes = {
  .name = "myTouchGFX",
  .stack_size = 10000 * 4,
  .priority = (osPriority_t) osPriorityNormal,
};
/* Definitions for adcTask */
osThreadId_t adcTaskHandle;
const osThreadAttr_t adcTask_attributes = {
  .name = "adcTask",
  .stack_size = 512 * 4,
  .priority = (osPriority_t) osPriorityBelowNormal,
};
/* Definitions for tsTask */
osThreadId_t tsTaskHandle;
const osThreadAttr_t tsTask_attributes = {
  .name = "tsTask",
  .stack_size = 1000 * 4,
  .priority = (osPriority_t) osPriorityNormal1,
};
/* Definitions for CanTask */
osThreadId_t CanTaskHandle;
const osThreadAttr_t CanTask_attributes = {
  .name = "CanTask",
  .stack_size = 512 * 4,
  .priority = (osPriority_t) osPriorityNormal,
};
/* Definitions for adcQueue */
osMessageQueueId_t adcQueueHandle;
const osMessageQueueAttr_t adcQueue_attributes = {
  .name = "adcQueue"
};
/* Definitions for butQueue */
osMessageQueueId_t butQueueHandle;
const osMessageQueueAttr_t butQueue_attributes = {
  .name = "butQueue"
};
/* Definitions for ts_Touch */
osMessageQueueId_t ts_TouchHandle;
const osMessageQueueAttr_t ts_Touch_attributes = {
  .name = "ts_Touch"
};
/* Definitions for canQueue */
osMessageQueueId_t canQueueHandle;
const osMessageQueueAttr_t canQueue_attributes = {
  .name = "canQueue"
};

void StartDefaultTask(void *argument);
void StartTGFXTask(void *argument);
void StartADCTask(void *argument);
void StartTS(void *argument);
void StartTask05(void *argument);

void MX_FREERTOS_Init(void); /* (MISRA C 2004 rule 8.1) */

void MX_FREERTOS_Init(void) {

  /* Create the queue(s) */
  /* creation of adcQueue */
  adcQueueHandle = osMessageQueueNew (4, sizeof(uint16_t), &adcQueue_attributes);

  /* creation of butQueue */
  butQueueHandle = osMessageQueueNew (8, sizeof(uint8_t), &butQueue_attributes);

  /* creation of ts_Touch */
  ts_TouchHandle = osMessageQueueNew (12, sizeof(uint16_t), &ts_Touch_attributes);

  /* creation of canQueue */
  canQueueHandle = osMessageQueueNew (64, sizeof(uint8_t), &canQueue_attributes);

  /* USER CODE BEGIN RTOS_QUEUES */
  /* add queues, ... */
  butQueueHandle = osMessageQueueNew (8, sizeof(Msg_Button_State), &butQueue_attributes);
  ts_TouchHandle = osMessageQueueNew (12, sizeof(TS_StateTypeDef), &ts_Touch_attributes);
  /* USER CODE END RTOS_QUEUES */

  /* Create the thread(s) */
  /* creation of defaultTask */
  defaultTaskHandle = osThreadNew(StartDefaultTask, NULL, &defaultTask_attributes);

  /* creation of myTouchGFX */
  myTouchGFXHandle = osThreadNew(StartTGFXTask, NULL, &myTouchGFX_attributes);

  /* creation of adcTask */
  adcTaskHandle = osThreadNew(StartADCTask, NULL, &adcTask_attributes);

  /* creation of tsTask */
  tsTaskHandle = osThreadNew(StartTS, NULL, &tsTask_attributes);

  /* creation of CanTask */
  CanTaskHandle = osThreadNew(StartTask05, NULL, &CanTask_attributes);

}

void StartDefaultTask(void *argument)
{
  /* USER CODE BEGIN StartDefaultTask */
  Msg_Button_State button;
  uint8_t count_rst=0;
  /* Infinite loop */
  for(;;)
  {
	  HAL_GPIO_TogglePin(LED3_GPIO_Port, LED3_Pin);
	  button.sw1 = HAL_GPIO_ReadPin(SW1_GPIO_Port,SW1_Pin);
	  button.sw4 = HAL_GPIO_ReadPin(SW4_GPIO_Port, SW4_Pin);
	  button.sw5 = HAL_GPIO_ReadPin(SW5_GPIO_Port, SW5_Pin);
	  button.sw8 = HAL_GPIO_ReadPin(SOFT_RST_GPIO_Port,SOFT_RST_Pin);
	  if(button.sw8)
	   {

		  if(++count_rst>10)
		   {
			  __NVIC_SystemReset();
		   }
	   }
	  else
	   {
		  count_rst=0;
	   }
	  osMessageQueuePut(butQueueHandle,&button,0,0);
	  osDelay(200);
  }
  /* USER CODE END StartDefaultTask */
}

void StartTGFXTask(void *argument)
{
  /* USER CODE BEGIN StartTGFXTask */
	MX_TouchGFX_Process();
  /* Infinite loop */
  for(;;)
  {
    osDelay(10);
  }
  /* USER CODE END StartTGFXTask */
}

void StartADCTask(void *argument)
{
  /* USER CODE BEGIN StartADCTask */
  /* Infinite loop */
  for(;;)
  {
	  HAL_ADC_Start(&hadc3);
	  HAL_ADC_PollForConversion(&hadc3,10);
	  uint16_t adcValue = HAL_ADC_GetValue(&hadc3);
	  HAL_ADC_Stop(&hadc3);
	  // 33V -- 4095
	  // Voltage_in -- adcValue
	  // adcValue*33 = Voltage_in*4095
	  // Voltage_in = adcValue*33/4095;
	  Voltage_in = adcValue*33/4095;
	  osMessageQueuePut(adcQueueHandle, &Voltage_in ,0 , 0);
	  osDelay(100);
  }
  /* USER CODE END StartADCTask */
}

void StartTS(void *argument)
{
  /* USER CODE BEGIN StartTS */
	TS_StateTypeDef msg_ts;
  /* Infinite loop */
  for(;;)
  {
	  BSP_TS_GetState(&msg_ts);
	  if(msg_ts.touchDetected)
	   {
		  osMessageQueuePut(ts_TouchHandle,&msg_ts, 0, 0);
	   }
	  osDelay(100);
  }
  /* USER CODE END StartTS */
}

void StartTask05(void *argument)
{
  for(;;)
  {
    osDelay(1);
  }
}
